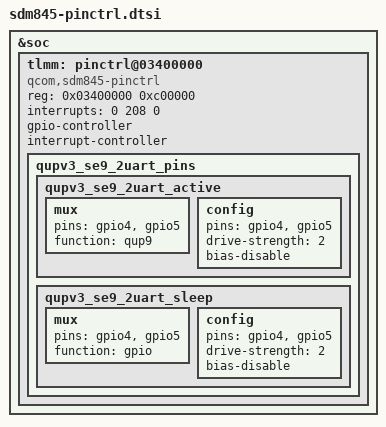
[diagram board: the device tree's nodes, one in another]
// SPDX-License-Identifier: GPL-2.0
/*
 * Copyright (c) 2018, The Linux Foundation. All rights reserved.
 */

&soc {
	tlmm: pinctrl@03400000 {
		compatible = "qcom,sdm845-pinctrl";
		reg = <0x03400000 0xc00000>;
		interrupts = <0 208 0>;
		gpio-controller;
		#gpio-cells = <2>;
		interrupt-controller;
		#interrupt-cells = <2>;

		qupv3_se9_2uart_pins: qupv3_se9_2uart_pins {
			qupv3_se9_2uart_active: qupv3_se9_2uart_active {
				mux {
					pins = "gpio4", "gpio5";
					function = "qup9";
				};

				config {
					pins = "gpio4", "gpio5";
					drive-strength = <2>;
					bias-disable;
				};
			};

			qupv3_se9_2uart_sleep: qupv3_se9_2uart_sleep {
				mux {
					pins = "gpio4", "gpio5";
					function = "gpio";
				};

				config {
					pins = "gpio4", "gpio5";
					drive-strength = <2>;
					bias-disable;
				};
			};
		};
	};
};
